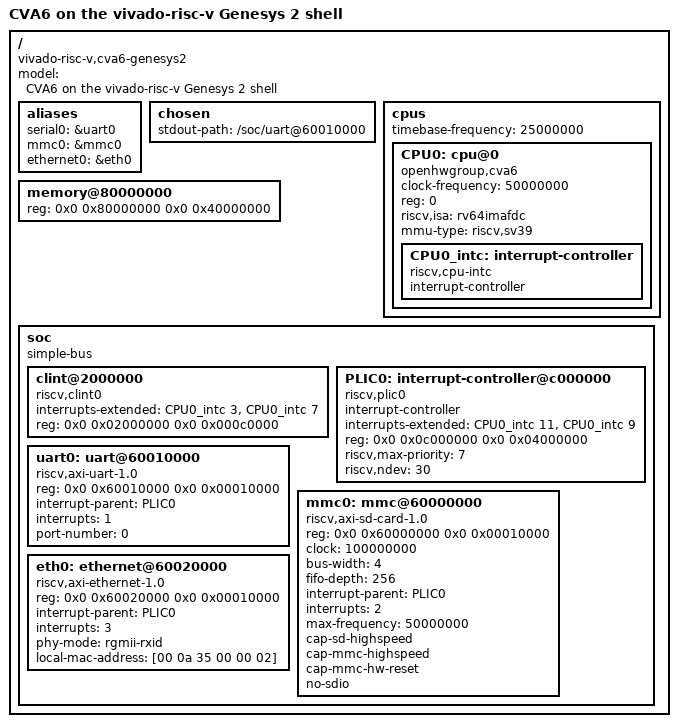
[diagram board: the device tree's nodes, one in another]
/dts-v1/;

/ {
  #address-cells = <2>;
  #size-cells = <2>;
  compatible = "vivado-risc-v,cva6-genesys2";
  model = "CVA6 on the vivado-risc-v Genesys 2 shell";

  aliases {
    serial0 = &uart0;
    mmc0 = &mmc0;
    ethernet0 = &eth0;
  };

  chosen {
    stdout-path = "/soc/uart@60010000";
  };

  cpus {
    #address-cells = <1>;
    #size-cells = <0>;
    timebase-frequency = <25000000>;

    CPU0: cpu@0 {
      clock-frequency = <50000000>;
      compatible = "openhwgroup,cva6", "riscv";
      device_type = "cpu";
      reg = <0>;
      status = "okay";
      riscv,isa = "rv64imafdc";
      mmu-type = "riscv,sv39";

      CPU0_intc: interrupt-controller {
        #address-cells = <0>;
        #interrupt-cells = <1>;
        compatible = "riscv,cpu-intc";
        interrupt-controller;
      };
    };
  };

  memory@80000000 {
    device_type = "memory";
    reg = <0x0 0x80000000 0x0 0x40000000>;
  };

  soc {
    #address-cells = <2>;
    #size-cells = <2>;
    compatible = "simple-bus";
    ranges;

    clint@2000000 {
      compatible = "riscv,clint0";
      interrupts-extended = <&CPU0_intc 3 &CPU0_intc 7>;
      reg = <0x0 0x02000000 0x0 0x000c0000>;
    };

    PLIC0: interrupt-controller@c000000 {
      #address-cells = <0>;
      #interrupt-cells = <1>;
      compatible = "riscv,plic0";
      interrupt-controller;
      interrupts-extended = <&CPU0_intc 11 &CPU0_intc 9>;
      reg = <0x0 0x0c000000 0x0 0x04000000>;
      riscv,max-priority = <7>;
      riscv,ndev = <30>;
    };

    uart0: uart@60010000 {
      compatible = "riscv,axi-uart-1.0";
      reg = <0x0 0x60010000 0x0 0x00010000>;
      interrupt-parent = <&PLIC0>;
      interrupts = <1>;
      port-number = <0>;
    };

    mmc0: mmc@60000000 {
      compatible = "riscv,axi-sd-card-1.0";
      reg = <0x0 0x60000000 0x0 0x00010000>;
      clock = <100000000>;
      bus-width = <4>;
      fifo-depth = <256>;
      interrupt-parent = <&PLIC0>;
      interrupts = <2>;
      max-frequency = <50000000>;
      cap-sd-highspeed;
      cap-mmc-highspeed;
      cap-mmc-hw-reset;
      no-sdio;
    };

    eth0: ethernet@60020000 {
      compatible = "riscv,axi-ethernet-1.0";
      reg = <0x0 0x60020000 0x0 0x00010000>;
      interrupt-parent = <&PLIC0>;
      interrupts = <3>;
      phy-mode = "rgmii-rxid";
      local-mac-address = [00 0a 35 00 00 02];
    };
  };
};
